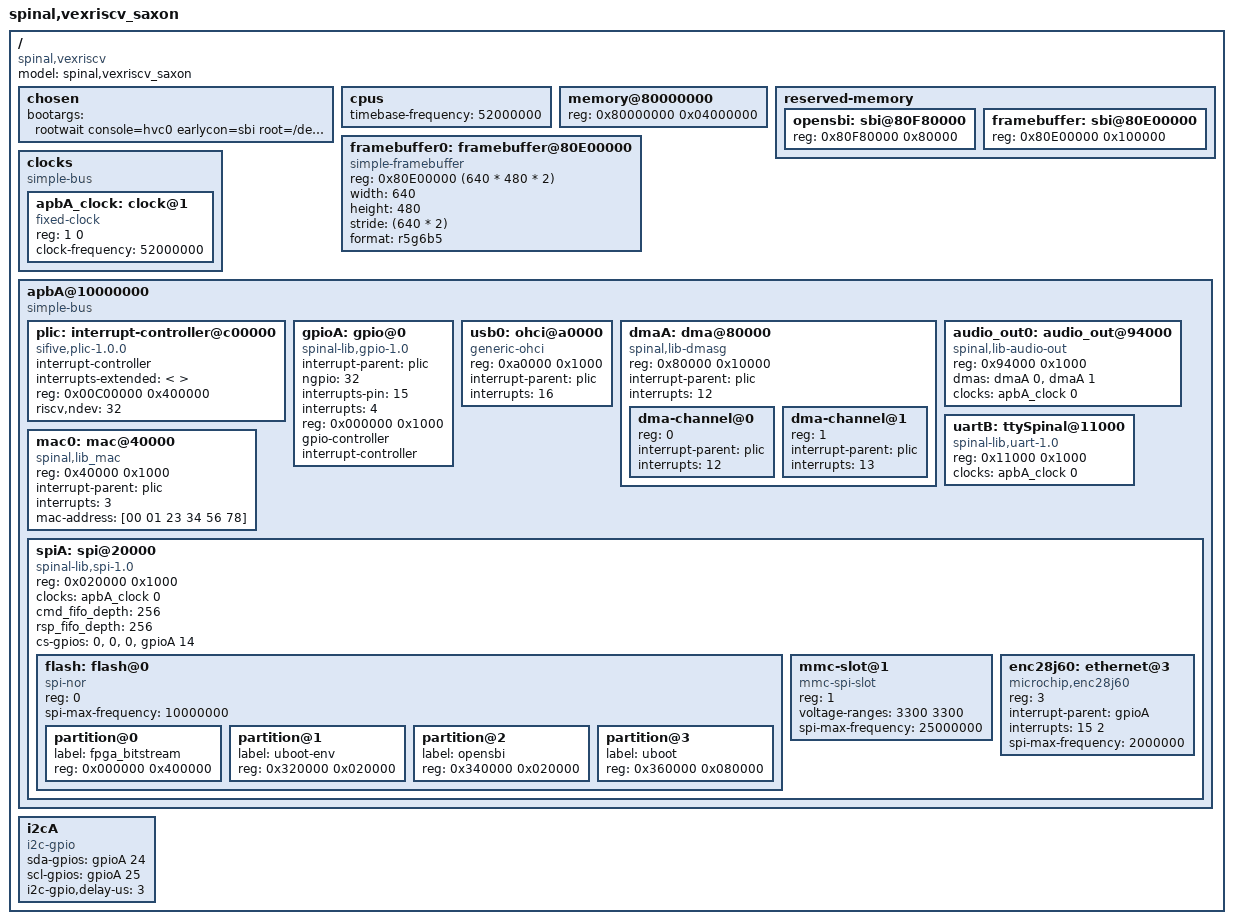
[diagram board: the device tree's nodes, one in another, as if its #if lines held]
/dts-v1/;
#include <dt-bindings/gpio/gpio.h>
#include <dt-bindings/input/input.h>
#include <dt-bindings/interrupt-controller/irq.h>

#if SAXON_FPU == 1
#define SAXON_CPU_ISA "rv32imafdc"
#else
#define SAXON_CPU_ISA "rv32imac"
#endif

/ {
    #address-cells = <0x1>;
    #size-cells = <0x1>;
    compatible = "spinal,vexriscv";
    model = "spinal,vexriscv_saxon";

    chosen {
        bootargs = "rootwait console=hvc0 earlycon=sbi root=/dev/mmcblk0p2 init=/sbin/init mmc_core.use_spi_crc=0";

        //bootargs = "rootwait console=hvc0 earlycon=sbi root=/dev/ram0 init=/sbin/init mmc_core.use_spi_crc=0";
        //linux,initrd-start = <0x81000000>;
        //linux,initrd-end =   <0x82000000>;
    };

    cpus {
        #address-cells = <0x1>;
        #size-cells = <0x0>;
        timebase-frequency = <52000000>;
        #include <boards/common/dts/linux_cpu.dts>
    };


    memory@80000000 {
        device_type = "memory";
        #if SDRAM_SIZE == 64
        reg = <0x80000000 0x04000000>;
        #else
        reg = <0x80000000 0x02000000>;
        #endif
    };

    reserved-memory {
        #address-cells = <1>;
        #size-cells = <1>;
        ranges;

        opensbi: sbi@80F80000 {
            reg = <0x80F80000 0x80000>;
        };
        framebuffer: sbi@80E00000 {
            reg = <0x80E00000 0x100000>;
        };
    };

    framebuffer0: framebuffer@80E00000 {
        compatible = "simple-framebuffer";
        reg = <0x80E00000 (640 * 480 * 2)>;
        width = <640>;
        height = <480>;
        stride = <(640 * 2)>;
        format = "r5g6b5";
    };

    clocks {
        compatible = "simple-bus";
        #address-cells = <1>;
        #size-cells = <0>;

        apbA_clock: clock@1 {
            compatible = "fixed-clock";
            reg = <1 0>;
            #clock-cells = <0>;
            clock-frequency = <52000000>;
        };
    };

    apbA@10000000 {
        compatible = "simple-bus";
        #address-cells = <0x1>;
        #size-cells = <0x1>;
        ranges = <0x0 0x10000000 0x01000000>;

        plic: interrupt-controller@c00000 {
            compatible = "sifive,plic-1.0.0", "sifive,fu540-c000-plic";
            #interrupt-cells = <1>;
            interrupt-controller;
            interrupts-extended = <
                #include <boards/common/dts/linux_plic_link.dts>
            >;
            reg = <0x00C00000 0x400000>;
            riscv,ndev = <32>;
        };

        gpioA: gpio@0 {
            compatible = "spinal-lib,gpio-1.0";
            interrupt-parent = <&plic>;
            ngpio = <32>;
            interrupts-pin = <15>;
            interrupts     = < 4>;
            reg = <0x000000 0x1000>;
            gpio-controller;
            #gpio-cells = <2>;
            interrupt-controller;
            #interrupt-cells = <2>;
        };


#if SAXON_USB_HOST == 1
        usb0: ohci@a0000 {
          compatible = "generic-ohci";
          reg = <0xa0000 0x1000>;
          interrupt-parent = <&plic>;
          interrupts = <16>;
        };
#endif

        dmaA: dma@80000 {
            compatible = "spinal,lib-dmasg";
            reg = <0x80000 0x10000>;
            interrupt-parent = <&plic>;
            interrupts = <12>;

            #dma-cells = <1>;
            #address-cells = <1>;
            #size-cells = <0>;
            dma-channel@0 {
                reg = <0>;
                interrupt-parent = <&plic>;
                interrupts = <12>;
            };
            dma-channel@1 {
                reg = <1>;
                interrupt-parent = <&plic>;
                interrupts = <13>;
            };
        };

        audio_out0: audio_out@94000 {
            compatible = "spinal,lib-audio-out";
            reg = <0x94000 0x1000>;

            dmas = <&dmaA 0>, <&dmaA 1>;
            dma-names = "rx", "tx";

            clocks = <&apbA_clock 0>;
        };


        uartB: ttySpinal@11000 {
                compatible = "spinal-lib,uart-1.0";
                reg = <0x11000 0x1000>;
                clocks = <&apbA_clock 0>;
                //interrupt-parent = <&plic>;
                //interrupts = <2>;
        };

        mac0: mac@40000 {
            compatible = "spinal,lib_mac";
            reg = <0x40000 0x1000>;
            interrupt-parent = <&plic>;
            interrupts = <3>;
            mac-address = [00 01 23 34 56 78];
        };

        spiA: spi@20000 {
            compatible = "spinal-lib,spi-1.0";
            #address-cells = <1>;
            #size-cells = <0>;
            reg = <0x020000 0x1000>;
            clocks = <&apbA_clock 0>;
            cmd_fifo_depth = <256>;
            rsp_fifo_depth = <256>;
            cs-gpios = <0>, <0>, <0>, <&gpioA 14 0>;

            flash: flash@0 {
                #address-cells = <1>;
                #size-cells = <1>;
                compatible = "spi-nor";
                reg = <0>;
                spi-max-frequency = <10000000>;
                partition@0 {
                    label = "fpga_bitstream";
                    reg = <0x000000 0x400000>;
                };
                partition@1 {
                    label = "uboot-env";
                    reg = <0x320000 0x020000>;
                };
                partition@2 {
                    label = "opensbi";
                    reg = <0x340000 0x020000>;
                };
                partition@3 {
                    label = "uboot";
                    reg = <0x360000 0x080000>;
                };
            };

            mmc-slot@1 {
                compatible = "mmc-spi-slot";
                reg = <1>;
                voltage-ranges = <3300 3300>;
                spi-max-frequency = <25000000>;
            };

            /*spidev@2{
                compatible = "spidev";
                spi-max-frequency = <25000000>;
                reg = <2>;
            };*/

            enc28j60: ethernet@3 {
                compatible = "microchip,enc28j60";
                reg = <3>;
                interrupt-parent = <&gpioA>;
                interrupts = <15 2>; //IRQ_TYPE_EDGE_FALLING
                spi-max-frequency = <2000000>;
            };
        };
    };

    i2cA: i2cA {
        compatible = "i2c-gpio";
        sda-gpios = <&gpioA 24 (GPIO_ACTIVE_HIGH | GPIO_OPEN_DRAIN)>;
        scl-gpios = <&gpioA 25 (GPIO_ACTIVE_HIGH | GPIO_OPEN_DRAIN)>;
        i2c-gpio,delay-us = <3>;
        #address-cells = <1>;
        #size-cells = <0>;
    };
};


